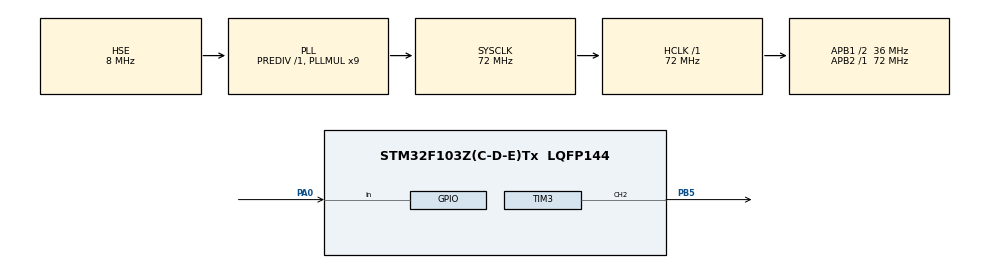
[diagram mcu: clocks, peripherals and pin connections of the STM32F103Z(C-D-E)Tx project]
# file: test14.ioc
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Mcu.Family=STM32F1
Mcu.Name=STM32F103Z(C-D-E)Tx
Mcu.Package=LQFP144
NVIC.PriorityGroup=NVIC_PRIORITYGROUP_4
OSC_IN.Mode=HSE-External-Oscillator
OSC_IN.Signal=RCC_OSC_IN
OSC_OUT.Mode=HSE-External-Oscillator
OSC_OUT.Signal=RCC_OSC_OUT
PA0-WKUP.GPIO_PuPd=GPIO_PULLDOWN
PA0-WKUP.Signal=GPIO_Input
PA13.Mode=Serial_Wire
PA13.Signal=SYS_JTMS-SWDIO
PA14.Mode=Serial_Wire
PA14.Signal=SYS_JTCK-SWCLK
PB5.GPIO_Speed=GPIO_SPEED_FREQ_HIGH
PB5.Signal=S_TIM3_CH2
ProjectManager.HeapSize=0x200
ProjectManager.StackSize=0x400
ProjectManager.TargetToolchain=MDK-ARM V5.32
RCC.AHBFreq_Value=72000000
RCC.APB1CLKDivider=RCC_HCLK_DIV2
RCC.APB1Freq_Value=36000000
RCC.APB1TimFreq_Value=72000000
RCC.APB2Freq_Value=72000000
RCC.APB2TimFreq_Value=72000000
RCC.HCLKFreq_Value=72000000
RCC.PLLMUL=RCC_PLL_MUL9
RCC.PLLSourceVirtual=RCC_PLLSOURCE_HSE
RCC.SYSCLKFreq_VALUE=72000000
RCC.SYSCLKSource=RCC_SYSCLKSOURCE_PLLCLK
RCC.USBFreq_Value=72000000
SH.S_TIM3_CH2.0=TIM3_CH2,PWM Generation2 CH2
TIM3.Channel-PWM\ Generation2\ CH2=TIM_CHANNEL_2
TIM3.OCPolarity_2=TIM_OCPOLARITY_LOW
TIM3.Period=500-1
TIM3.Prescaler=72-1
TIM3.Pulse-PWM\ Generation2\ CH2=10
VP_TIM3_VS_ClockSourceINT.Mode=Internal
board=custom

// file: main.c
/* USER CODE BEGIN Header */
/**
 ******************************************************************************
 * @file           : main.c
 * @brief          : Main program body
 ******************************************************************************
 * @attention
 *
 * Copyright (c) 2023 STMicroelectronics.
 * All rights reserved.
 *
 * This software is licensed under terms that can be found in the LICENSE file
 * in the root directory of this software component.
 * If no LICENSE file comes with this software, it is provided AS-IS.
 *
 ******************************************************************************
 */
/* USER CODE END Header */
#include "main.h"
#include "tim.h"
#include "gpio.h"
#include "stdbool.h"

/* USER CODE BEGIN Includes */
uint8_t pb5_duty = 250;
bool key_flag = false;
/* USER CODE END Includes */

/* USER CODE BEGIN PV */
void key_scan()
{
  if (HAL_GPIO_ReadPin(GPIOA, GPIO_PIN_0) == GPIO_PIN_SET)
  {
    HAL_Delay(10);
    if (HAL_GPIO_ReadPin(GPIOA, GPIO_PIN_0) == GPIO_PIN_SET)
    {
      while ((HAL_GPIO_ReadPin(GPIOA, GPIO_PIN_0) == GPIO_PIN_SET))
        ;
      key_flag = true; // 按键按下
    }
  }
}

void key_proc()
{
  if (key_flag)
  {
    pb5_duty += 10;
    if (pb5_duty >= 300)
      pb5_duty = 10;
    __HAL_TIM_SetCompare(&htim3, TIM_CHANNEL_2, pb5_duty);
    key_flag = false;
  }
}
/* USER CODE END PV */

void SystemClock_Config(void);

int main(void)
{

  /* MCU Configuration--------------------------------------------------------*/

  /* Reset of all peripherals, Initializes the Flash interface and the Systick. */
  HAL_Init();

  /* Configure the system clock */
  SystemClock_Config();

  /* Initialize all configured peripherals */
  MX_GPIO_Init();
  MX_TIM3_Init();
  /* USER CODE BEGIN 2 */
  HAL_TIM_PWM_Start(&htim3, TIM_CHANNEL_2);
  __HAL_TIM_SetCompare(&htim3, TIM_CHANNEL_2, pb5_duty);

  uint8_t dir = 1;
  uint16_t led0pwmval = 0;
  /* USER CODE END 2 */

  /* Infinite loop */
  /* USER CODE BEGIN WHILE */
  while (1)
  {
    // key_scan();
    // key_proc();
    HAL_Delay(10);
    if (dir)
      led0pwmval++; // dir==1 led0pwmval 递增
    else
      led0pwmval--; // dir==0 led0pwmval 递减
    if (led0pwmval > 300)
      dir = 0; // led0pwmval 到达 300 后，方向为递减
    if (led0pwmval == 0)
      dir = 1;                                               // led0pwmval 递减到 0 后，方向改为递增
    __HAL_TIM_SetCompare(&htim3, TIM_CHANNEL_2, led0pwmval); // 修改比较值，修改占空比
    /* USER CODE END WHILE */

  }
}

void SystemClock_Config(void)
{
  RCC_OscInitTypeDef RCC_OscInitStruct = {0};
  RCC_ClkInitTypeDef RCC_ClkInitStruct = {0};

  /** Initializes the RCC Oscillators according to the specified parameters
   * in the RCC_OscInitTypeDef structure.
   */
  RCC_OscInitStruct.OscillatorType = RCC_OSCILLATORTYPE_HSE;
  RCC_OscInitStruct.HSEState = RCC_HSE_ON;
  RCC_OscInitStruct.HSEPredivValue = RCC_HSE_PREDIV_DIV1;
  RCC_OscInitStruct.HSIState = RCC_HSI_ON;
  RCC_OscInitStruct.PLL.PLLState = RCC_PLL_ON;
  RCC_OscInitStruct.PLL.PLLSource = RCC_PLLSOURCE_HSE;
  RCC_OscInitStruct.PLL.PLLMUL = RCC_PLL_MUL9;
  if (HAL_RCC_OscConfig(&RCC_OscInitStruct) != HAL_OK)
  {
    Error_Handler();
  }

  /** Initializes the CPU, AHB and APB buses clocks
   */
  RCC_ClkInitStruct.ClockType = RCC_CLOCKTYPE_HCLK | RCC_CLOCKTYPE_SYSCLK | RCC_CLOCKTYPE_PCLK1 | RCC_CLOCKTYPE_PCLK2;
  RCC_ClkInitStruct.SYSCLKSource = RCC_SYSCLKSOURCE_PLLCLK;
  RCC_ClkInitStruct.AHBCLKDivider = RCC_SYSCLK_DIV1;
  RCC_ClkInitStruct.APB1CLKDivider = RCC_HCLK_DIV2;
  RCC_ClkInitStruct.APB2CLKDivider = RCC_HCLK_DIV1;

  if (HAL_RCC_ClockConfig(&RCC_ClkInitStruct, FLASH_LATENCY_2) != HAL_OK)
  {
    Error_Handler();
  }
}

void Error_Handler(void)
{
  __disable_irq();
  while (1)
  {
  }
}
